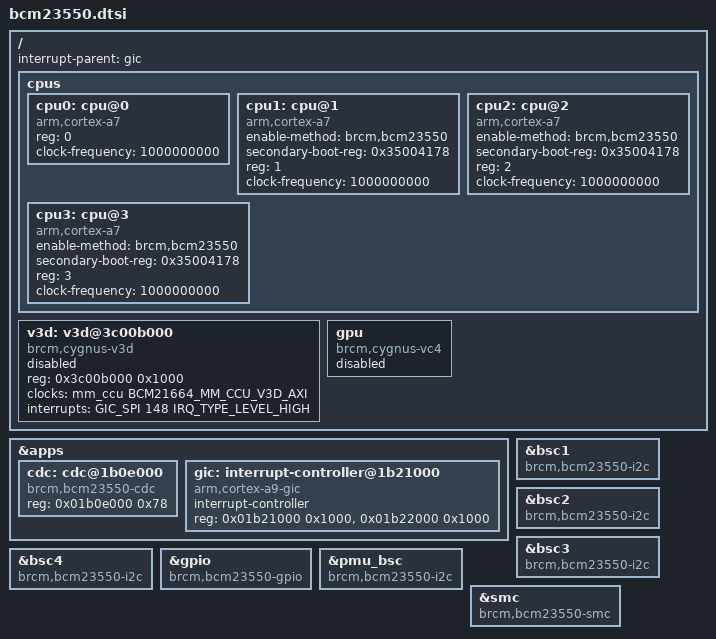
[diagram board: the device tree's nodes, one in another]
// SPDX-License-Identifier: BSD-3-Clause
/*
 * Device tree for the BCM23550 SoC.
 *
 * Copyright (C) 2016 Broadcom
 */

#include "bcm2166x-common.dtsi"

/ {
	interrupt-parent = <&gic>;

	cpus {
		#address-cells = <1>;
		#size-cells = <0>;

		cpu0: cpu@0 {
			device_type = "cpu";
			compatible = "arm,cortex-a7";
			reg = <0>;
			clock-frequency = <1000000000>;
		};

		cpu1: cpu@1 {
			device_type = "cpu";
			compatible = "arm,cortex-a7";
			enable-method = "brcm,bcm23550";
			secondary-boot-reg = <0x35004178>;
			reg = <1>;
			clock-frequency = <1000000000>;
		};

		cpu2: cpu@2 {
			device_type = "cpu";
			compatible = "arm,cortex-a7";
			enable-method = "brcm,bcm23550";
			secondary-boot-reg = <0x35004178>;
			reg = <2>;
			clock-frequency = <1000000000>;
		};

		cpu3: cpu@3 {
			device_type = "cpu";
			compatible = "arm,cortex-a7";
			enable-method = "brcm,bcm23550";
			secondary-boot-reg = <0x35004178>;
			reg = <3>;
			clock-frequency = <1000000000>;
		};
	};

	/*
	 * VideoCore-IV 3D core (V3D).  Same "gen 4" IP the mainline vc4
	 * driver targets via the Cygnus binding.  The register block lives
	 * in the MM peripheral region at 0x3c00b000 and is clocked by the
	 * MM CCU's v3d_axi clock.  Disabled by default: it only works once
	 * the MM power domain is powered, which is board/bootloader
	 * dependent and not yet modelled in mainline - enable per board.
	 *
	 * V3D IRQ: downstream IRQ_GRAPHICS == BCM_INT_ID_RESERVED148, i.e.
	 * raw GIC hwirq 180 -> GIC_SPI (180 - 32) = 148, level high.
	 */
	v3d: v3d@3c00b000 {
		compatible = "brcm,cygnus-v3d";
		reg = <0x3c00b000 0x1000>;
		clocks = <&mm_ccu BCM21664_MM_CCU_V3D_AXI>;
		clock-names = "v3d_clk";
		interrupts = <GIC_SPI 148 IRQ_TYPE_LEVEL_HIGH>;
		status = "disabled";
	};

	/*
	 * vc4 component-master node.  Carries no registers; it exists so the
	 * vc4 DRM driver binds in render-only mode (V3D only, no KMS) and
	 * exposes /dev/dri/renderD128.  Enabled together with the v3d node.
	 */
	gpu: gpu {
		compatible = "brcm,cygnus-vc4";
		status = "disabled";
	};
};

&apps {
		cdc: cdc@1b0e000 {
			compatible = "brcm,bcm23550-cdc";
			reg = <0x01b0e000 0x78>;
		};

		gic: interrupt-controller@1b21000 {
			compatible = "arm,cortex-a9-gic";
			#interrupt-cells = <3>;
			#address-cells = <0>;
			interrupt-controller;
			reg = <0x01b21000 0x1000>,
			      <0x01b22000 0x1000>;
		};
};

&bsc1 {
	compatible = "brcm,bcm23550-i2c", "brcm,kona-i2c";
};

&bsc2 {
	compatible = "brcm,bcm23550-i2c", "brcm,kona-i2c";
};

&bsc3 {
	compatible = "brcm,bcm23550-i2c", "brcm,kona-i2c";
};

&bsc4 {
	compatible = "brcm,bcm23550-i2c", "brcm,kona-i2c";
};

&gpio {
	compatible = "brcm,bcm23550-gpio", "brcm,kona-gpio";
};

&pmu_bsc {
	compatible = "brcm,bcm23550-i2c", "brcm,kona-i2c";
};

&smc {
	compatible = "brcm,bcm23550-smc", "brcm,kona-smc";
};
